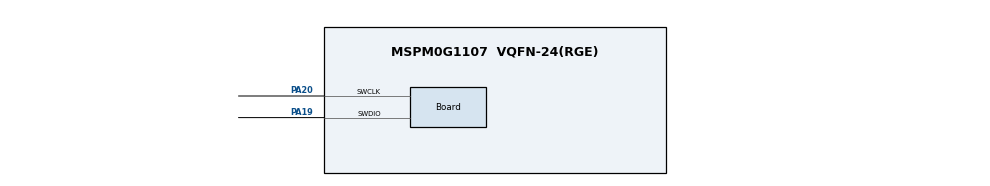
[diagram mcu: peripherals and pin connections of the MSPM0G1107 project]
/**
 * These arguments were used when this file was generated. They will be automatically applied on subsequent loads
 * via the GUI or CLI. Run CLI with '--help' for additional information on how to override these arguments.
 * @cliArgs --device "MSPM0G110X" --part "Default" --package "VQFN-24(RGE)" --product "mspm0_sdk@2.04.00.06"
 * @v2CliArgs --device "MSPM0G1107" --package "VQFN-24(RGE)" --product "mspm0_sdk@2.04.00.06"
 * @versions {"tool":"1.22.0+3893"}
 */

/**
 * Import the modules used in this configuration.
 */
const ADC12         = scripting.addModule("/ti/driverlib/ADC12", {}, false);
const ADC121        = ADC12.addInstance();
const GPIO          = scripting.addModule("/ti/driverlib/GPIO", {}, false);
const GPIO1         = GPIO.addInstance();
const GPIO2         = GPIO.addInstance();
const SYSCTL        = scripting.addModule("/ti/driverlib/SYSCTL");
const VREF          = scripting.addModule("/ti/driverlib/VREF");
const ProjectConfig = scripting.addModule("/ti/project_config/ProjectConfig");

/**
 * Write custom configuration values to the imported modules.
 */
const multiplier2         = system.clockTree["PLL_QDIV"];
multiplier2.multiplyValue = 5;

ADC121.$name                 = "ADC12_0";
ADC121.sampClkDiv            = "DL_ADC12_CLOCK_DIVIDE_4";
ADC121.repeatMode            = true;
ADC121.adcMem0chansel        = "DL_ADC12_INPUT_CHAN_15";
ADC121.adcMem0vref           = "VREF";
ADC121.adcMem1chansel        = "DL_ADC12_INPUT_CHAN_2";
ADC121.adcMem0_name          = "BATTERY_VOLTAGE";
ADC121.adcMem1_name          = "INAMP_DIFFERENTIAL";
ADC121.adcMem2_name          = "INAMP_REFFERENCE";
ADC121.adcMem2chansel        = "DL_ADC12_INPUT_CHAN_1";
ADC121.samplingOperationMode = "sequence";
ADC121.endAdd                = 2;
ADC121.peripheral.$assign    = "ADC0";
ADC121.adcPin2Config.$name   = "ti_driverlib_gpio_GPIOPinGeneric1";
ADC121.adcPin1Config.$name   = "ti_driverlib_gpio_GPIOPinGeneric2";

const Board                       = scripting.addModule("/ti/driverlib/Board", {}, false);
Board.peripheral.$assign          = "DEBUGSS";
Board.peripheral.swclkPin.$assign = "PA20";
Board.peripheral.swdioPin.$assign = "PA19";

GPIO1.$name                           = "LED";
GPIO1.port                            = "PORTA";
GPIO1.associatedPins.create(2);
GPIO1.associatedPins[0].$name         = "RED_LED";
GPIO1.associatedPins[0].assignedPort  = "PORTA";
GPIO1.associatedPins[0].assignedPin   = "10";
GPIO1.associatedPins[0].driveStrength = "HIGH";
GPIO1.associatedPins[1].$name         = "YELLOW_LED";
GPIO1.associatedPins[1].assignedPin   = "11";
GPIO1.associatedPins[1].assignedPort  = "PORTA";
GPIO1.associatedPins[1].driveStrength = "HIGH";

GPIO2.$name                          = "INAMP";
GPIO2.port                           = "PORTA";
GPIO2.associatedPins.create(2);
GPIO2.associatedPins[0].$name        = "INAMP_ENABLE";
GPIO2.associatedPins[0].initialValue = "SET";
GPIO2.associatedPins[0].assignedPin  = "23";
GPIO2.associatedPins[1].$name        = "INAMP_LEAD_OFF";
GPIO2.associatedPins[1].direction    = "INPUT";
GPIO2.associatedPins[1].assignedPin  = "24";

SYSCTL.peripheral.$assign = "SYSCTL";

VREF.vrefPosPinConfig.$name = "ti_driverlib_gpio_GPIOPinGeneric0";

ProjectConfig.migrationCondition = true;

/**
 * Pinmux solution for unlocked pins/peripherals. This ensures that minor changes to the automatic solver in a future
 * version of the tool will not impact the pinmux you originally saw.  These lines can be completely deleted in order to
 * re-solve from scratch.
 */
ADC121.peripheral.adcPin2.$suggestSolution   = "PA25";
ADC121.peripheral.adcPin1.$suggestSolution   = "PA26";
GPIO1.associatedPins[0].pin.$suggestSolution = "PA10";
GPIO1.associatedPins[1].pin.$suggestSolution = "PA11";
GPIO2.associatedPins[0].pin.$suggestSolution = "PA23";
GPIO2.associatedPins[1].pin.$suggestSolution = "PA24";
VREF.peripheral.$suggestSolution             = "VREF";
VREF.peripheral.vrefPosPin.$suggestSolution  = "PA21";
